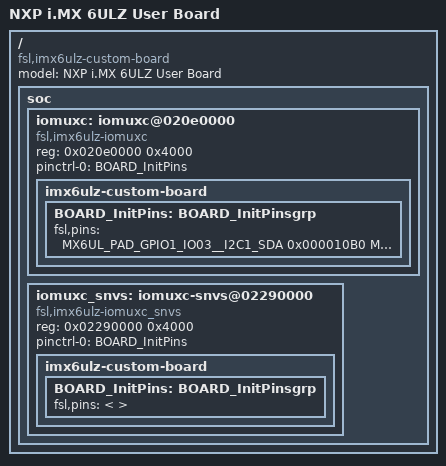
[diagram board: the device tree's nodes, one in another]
/***********************************************************************************************************************
 * This file was generated by the MCUXpresso Config Tools. Any manual edits made to this file
 * will be overwritten if the respective MCUXpresso Config Tools is used to update this file.
 **********************************************************************************************************************/

/*
 * TEXT BELOW IS USED AS SETTING FOR TOOLS *************************************
!!GlobalInfo
product: Pins v13.1
processor: MCIMX6Z0xxx09
package_id: MCIMX6Z0DVM09
mcu_data: ksdk2_0
processor_version: 13.0.0
 * BE CAREFUL MODIFYING THIS COMMENT - IT IS YAML SETTINGS FOR TOOLS ***********
 */


/dts-v1/;

#include "skeleton.dtsi"
#include "imx6ull-pinfunc.h"

/ {
    model = "NXP i.MX 6ULZ User Board";
    compatible = "fsl,imx6ulz-custom-board", "fsl,imx6ulz";

    soc {
        #address-cells = <1>;
        #size-cells = <1>;

        iomuxc: iomuxc@020e0000 {
            compatible = "fsl,imx6ulz-iomuxc";
            reg = <0x020e0000 0x4000>;
        };

        iomuxc_snvs: iomuxc-snvs@02290000 {
            compatible = "fsl,imx6ulz-iomuxc_snvs";
            reg = <0x02290000 0x4000>;
        };
    };
};

&iomuxc {
    pinctrl-names = "default_iomuxc";
    pinctrl-0 = <&BOARD_InitPins>;


    imx6ulz-custom-board {
        BOARD_InitPins: BOARD_InitPinsgrp {                /*!< Function assigned for the core: Cortex-A7[ca7] */
/*
 * TEXT BELOW IS USED AS SETTING FOR TOOLS *************************************
BOARD_InitPins:
- options: {callFromInitBoot: 'false', coreID: ca7}
- pin_list:
  - {pin_num: A2, peripheral: USDHC1, signal: 'usdhc_data, 3', pin_signal: SD1_DATA3}
  - {pin_num: B2, peripheral: USDHC1, signal: 'usdhc_data, 1', pin_signal: SD1_DATA1}
  - {pin_num: C2, peripheral: USDHC1, signal: usdhc_cmd, pin_signal: SD1_CMD}
  - {pin_num: B1, peripheral: USDHC1, signal: 'usdhc_data, 2', pin_signal: SD1_DATA2}
  - {pin_num: C1, peripheral: USDHC1, signal: usdhc_clk, pin_signal: SD1_CLK}
  - {pin_num: B3, peripheral: USDHC1, signal: 'usdhc_data, 0', pin_signal: SD1_DATA0}
  - {pin_num: G17, peripheral: I2C1, signal: i2c_scl, pin_signal: UART4_TX_DATA}
  - {pin_num: L17, peripheral: I2C1, signal: i2c_sda, pin_signal: GPIO1_IO03}
  - {pin_num: K16, peripheral: UART1, signal: uart_rx, pin_signal: UART1_RX_DATA}
  - {pin_num: K14, peripheral: UART1, signal: uart_tx, pin_signal: UART1_TX_DATA}
  - {pin_num: K15, peripheral: UART1, signal: uart_cts_b, pin_signal: UART1_CTS_B}
  - {pin_num: J14, peripheral: UART1, signal: uart_rts_b, pin_signal: UART1_RTS_B}
 * BE CAREFUL MODIFYING THIS COMMENT - IT IS YAML SETTINGS FOR TOOLS ***********
 */
            fsl,pins = <
                MX6UL_PAD_GPIO1_IO03__I2C1_SDA             0x000010B0
                MX6UL_PAD_SD1_CLK__USDHC1_CLK              0x000010B0
                MX6UL_PAD_SD1_CMD__USDHC1_CMD              0x000010B0
                MX6UL_PAD_SD1_DATA0__USDHC1_DATA0          0x000010B0
                MX6UL_PAD_SD1_DATA1__USDHC1_DATA1          0x000010B0
                MX6UL_PAD_SD1_DATA2__USDHC1_DATA2          0x000010B0
                MX6UL_PAD_SD1_DATA3__USDHC1_DATA3          0x000010B0
                MX6UL_PAD_UART1_CTS_B__UART1_DCE_CTS       0x000010B0
                MX6UL_PAD_UART1_RTS_B__UART1_DCE_RTS       0x000010B0
                MX6UL_PAD_UART1_RX_DATA__UART1_DCE_RX      0x000010B0
                MX6UL_PAD_UART1_TX_DATA__UART1_DCE_TX      0x000010B0
                MX6UL_PAD_UART4_TX_DATA__I2C1_SCL          0x000010B0
            >;
        };
    };
};

&iomuxc_snvs {
    pinctrl-names = "default_iomuxc_snvs";
    pinctrl-0 = <&BOARD_InitPins>;


    imx6ulz-custom-board {
        BOARD_InitPins: BOARD_InitPinsgrp {                /*!< Function assigned for the core: Cortex-A7[ca7] */
/*
 * TEXT BELOW IS USED AS SETTING FOR TOOLS *************************************
BOARD_InitPins:
- options: {callFromInitBoot: 'false', coreID: ca7}
- pin_list:
  - {pin_num: A2, peripheral: USDHC1, signal: 'usdhc_data, 3', pin_signal: SD1_DATA3}
  - {pin_num: B2, peripheral: USDHC1, signal: 'usdhc_data, 1', pin_signal: SD1_DATA1}
  - {pin_num: C2, peripheral: USDHC1, signal: usdhc_cmd, pin_signal: SD1_CMD}
  - {pin_num: B1, peripheral: USDHC1, signal: 'usdhc_data, 2', pin_signal: SD1_DATA2}
  - {pin_num: C1, peripheral: USDHC1, signal: usdhc_clk, pin_signal: SD1_CLK}
  - {pin_num: B3, peripheral: USDHC1, signal: 'usdhc_data, 0', pin_signal: SD1_DATA0}
  - {pin_num: G17, peripheral: I2C1, signal: i2c_scl, pin_signal: UART4_TX_DATA}
  - {pin_num: L17, peripheral: I2C1, signal: i2c_sda, pin_signal: GPIO1_IO03}
  - {pin_num: K16, peripheral: UART1, signal: uart_rx, pin_signal: UART1_RX_DATA}
  - {pin_num: K14, peripheral: UART1, signal: uart_tx, pin_signal: UART1_TX_DATA}
  - {pin_num: K15, peripheral: UART1, signal: uart_cts_b, pin_signal: UART1_CTS_B}
  - {pin_num: J14, peripheral: UART1, signal: uart_rts_b, pin_signal: UART1_RTS_B}
 * BE CAREFUL MODIFYING THIS COMMENT - IT IS YAML SETTINGS FOR TOOLS ***********
 */
            fsl,pins = <
            >;
        };
    };
};

/***********************************************************************************************************************
 * EOF
 **********************************************************************************************************************/
